# nrf54lm20a_enga_application register map
Vendor: Nordic Semiconductor; Series: nrf54l; File version: 1
CPU: CM33 r0p4, little endian, MPU, FPU, 3 interrupt priority bits, 270 interrupts, 4 SAU regions
Registers are 32-bit, read-write, reset 0x0 unless marked. A register's access mark holds for its fields unless they carry their own. Offsets are from the block's base; [hi:lo] are bit positions; lines under a group give offsets from that group; 'fields as' and 'values as' point back to an identical list.

## GLOBAL_PDM20_NS — Pulse Density Modulation (Digital Microphone) Interface 0
Base 0x400D0000
Same registers: GLOBAL_PDM21_NS 0x400D1000, GLOBAL_PDM20_S 0x500D0000, GLOBAL_PDM21_S 0x500D1000
0x00 TASKS_START wo — Starts continuous PDM transfer
  [0] TASKS_START
    1=Trigger task
0x04 TASKS_STOP wo — Stops PDM transfer
  [0] TASKS_STOP
    1=Trigger task
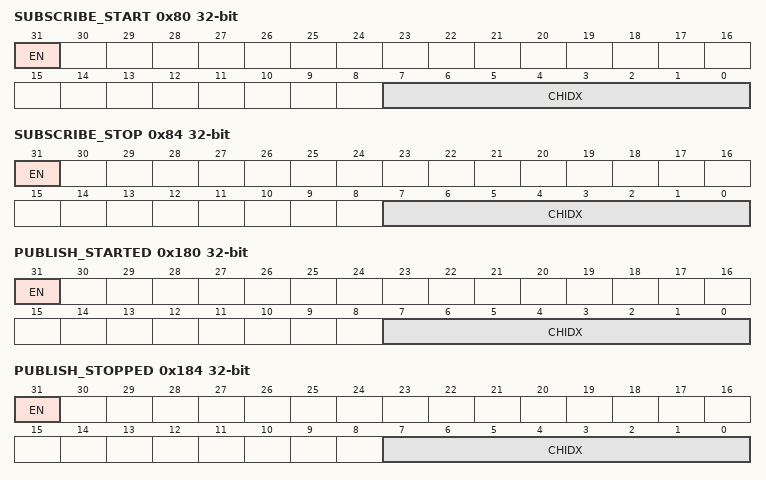
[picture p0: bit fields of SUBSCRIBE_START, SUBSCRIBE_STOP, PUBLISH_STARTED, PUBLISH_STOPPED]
0x80 SUBSCRIBE_START — Subscribe configuration for task START
  [31] EN
    0=Disabled (Disable subscription); 1=Enabled (Enable subscription)
  [7:0] CHIDX — DPPI channel that task START will subscribe to
0x84 SUBSCRIBE_STOP — Subscribe configuration for task STOP
  [31] EN
    values as SUBSCRIBE_START.EN
  [7:0] CHIDX — DPPI channel that task STOP will subscribe to
0x100 EVENTS_STARTED — PDM transfer has started
  [0] EVENTS_STARTED
    0=NotGenerated (Event not generated); 1=Generated (Event generated)
0x104 EVENTS_STOPPED — PDM transfer has finished
  [0] EVENTS_STOPPED
    values as EVENTS_STARTED.EVENTS_STARTED
0x108 EVENTS_END — The PDM has written the last sample specified by SAMPLE.MAXCNT (or the last sample after a STOP task has been received) to Data RAM
  [0] EVENTS_END
    values as EVENTS_STARTED.EVENTS_STARTED
0x10C EVENTS_OVERRUN — Samples lost due to DMA destination not available
  [0] EVENTS_OVERRUN
    values as EVENTS_STARTED.EVENTS_STARTED
0x110 EVENTS_DMA group — Peripheral events.
  0x00 BUSERROR — This event is generated if an error occurs during the bus transfer. This event is generated on an AHB / AXI error response.
    [0] BUSERROR
      values as EVENTS_STARTED.EVENTS_STARTED
0x180 PUBLISH_STARTED — Publish configuration for event STARTED
  [31] EN
    0=Disabled (Disable publishing); 1=Enabled (Enable publishing)
  [7:0] CHIDX — DPPI channel that event STARTED will publish to
0x184 PUBLISH_STOPPED — Publish configuration for event STOPPED
  [31] EN
    values as PUBLISH_STARTED.EN
  [7:0] CHIDX — DPPI channel that event STOPPED will publish to
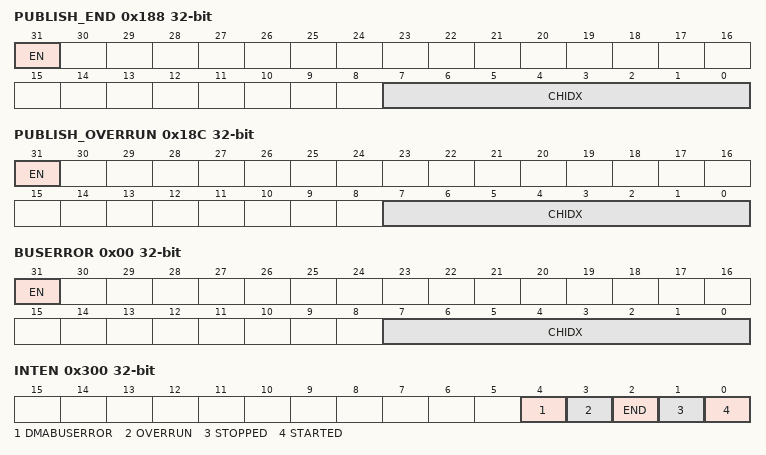
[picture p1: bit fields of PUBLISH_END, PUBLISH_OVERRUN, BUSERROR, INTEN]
0x188 PUBLISH_END — Publish configuration for event END
  [31] EN
    values as PUBLISH_STARTED.EN
  [7:0] CHIDX — DPPI channel that event END will publish to
0x18C PUBLISH_OVERRUN — Publish configuration for event OVERRUN
  [31] EN
    values as PUBLISH_STARTED.EN
  [7:0] CHIDX — DPPI channel that event OVERRUN will publish to
0x190 PUBLISH_DMA group — Publish configuration for events
  0x00 BUSERROR — Publish configuration for event DMA.BUSERROR
    [31] EN
      values as PUBLISH_STARTED.EN
    [7:0] CHIDX — DPPI channel that event DMA.BUSERROR will publish to
0x300 INTEN — Enable or disable interrupt
  [all] fields
    0=Disabled; 1=Enabled
  [4] DMABUSERROR — Enable or disable interrupt for event DMABUSERROR
  [3] OVERRUN — Enable or disable interrupt for event OVERRUN
  [2] END — Enable or disable interrupt for event END
  [1] STOPPED — Enable or disable interrupt for event STOPPED
  [0] STARTED — Enable or disable interrupt for event STARTED
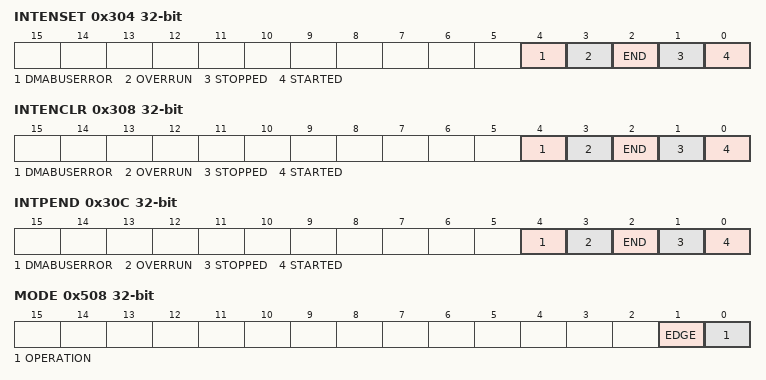
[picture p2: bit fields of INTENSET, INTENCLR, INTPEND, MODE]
0x304 INTENSET — Enable interrupt
  [all] fields
    on read: 0=Disabled (Read: Disabled); 1=Enabled (Read: Enabled) | on write: 1=Set (Enable)
  [4] DMABUSERROR — Write '1' to enable interrupt for event DMABUSERROR
  [3] OVERRUN — Write '1' to enable interrupt for event OVERRUN
  [2] END — Write '1' to enable interrupt for event END
  [1] STOPPED — Write '1' to enable interrupt for event STOPPED
  [0] STARTED — Write '1' to enable interrupt for event STARTED
0x308 INTENCLR — Disable interrupt
  [all] fields
    on read: 0=Disabled (Read: Disabled); 1=Enabled (Read: Enabled) | on write: 1=Clear (Disable)
  [4] DMABUSERROR — Write '1' to disable interrupt for event DMABUSERROR
  [3] OVERRUN — Write '1' to disable interrupt for event OVERRUN
  [2] END — Write '1' to disable interrupt for event END
  [1] STOPPED — Write '1' to disable interrupt for event STOPPED
  [0] STARTED — Write '1' to disable interrupt for event STARTED
0x30C INTPEND ro — Pending interrupts
  [all] fields
    on read: 0=NotPending (Read: Not pending); 1=Pending (Read: Pending)
  [4] DMABUSERROR — Read pending status of interrupt for event DMABUSERROR
  [3] OVERRUN — Read pending status of interrupt for event OVERRUN
  [2] END — Read pending status of interrupt for event END
  [1] STOPPED — Read pending status of interrupt for event STOPPED
  [0] STARTED — Read pending status of interrupt for event STARTED
0x500 ENABLE — PDM module enable register
  [0] ENABLE — Enable or disable PDM module
    0=Disabled; 1=Enabled
0x508 MODE — Defines the routing of the connected PDM microphone signals
  [1] EDGE — Defines on which PDM_CLK edge left (or mono) is sampled.
    0=LeftFalling (Left (or mono) is sampled on falling edge of PDM_CLK); 1=LeftRising (Left (or mono) is sampled on rising edge of PDM_CLK)
  [0] OPERATION — Mono or stereo operation Mono also disables the gated clock to the right filter bank
    0=Stereo (Sample and store one pair (left + right) of 16-bit samples per RAM word R=[31:16]; L=[15:0]); 1=Mono (Sample and store two successive left samples (16 bits each) per RAM word L1=[31:16]; L0=[15:0])
0x510 RXDLDATA ro — Left sample from filter output
  [15:0] RXDLDATA
0x514 RXDRDATA ro — Right sample from filter output
  [15:0] RXDRDATA
0x518 GAINL reset 0x28 — Left output gain adjustment
  [6:0] GAINL — Left output gain adjustment, in 0.5 dB steps, around the default module gain (see electrical parameters) 0x00 -20 dB gain adjust 0x01 -19.5 dB gain adjust (...) 0x27 -0.5 dB gain adjust 0x28 0 dB gain adjust 0x29 +0.5 dB gain adjust (...) 0x4F +19.5 dB gain adjust 0x50 +20 dB gain adjust
    0=MinGain (-20 dB gain adjustment (minimum)); 40=DefaultGain (0 dB gain adjustment); 80=MaxGain (+20 dB gain adjustment (maximum))
0x51C GAINR reset 0x28 — Right output gain adjustment
  [6:0] GAINR — Right output gain adjustment, in 0.5 dB steps, around the default module gain (see electrical parameters)
    values as GAINL.GAINL
0x520 RATIO reset 0x2 — Selects the decimation ratio between PDM_CLK and output sample rate. When RATIO is selected to be 'custom', the decimation rate should be set using the FILTER.CTRL field before setting the RATIO to 7 Change PRESCALER.DIVISOR accordingly.
  [2:0] RATIO — Selects the decimation ratio between PDM_CLK and output sample rate
    0=Ratio of 48; 1=Ratio of 50; 2=Ratio of 64; 3=Ratio of 80; 4=Ratio of 96; 5=Ratio of 150; 6=Ratio of 192; 7=Custom. The decimation rate can be changed using the FILTER.CTRL[31:25] bits
0x524 FILTER group — Unspecified
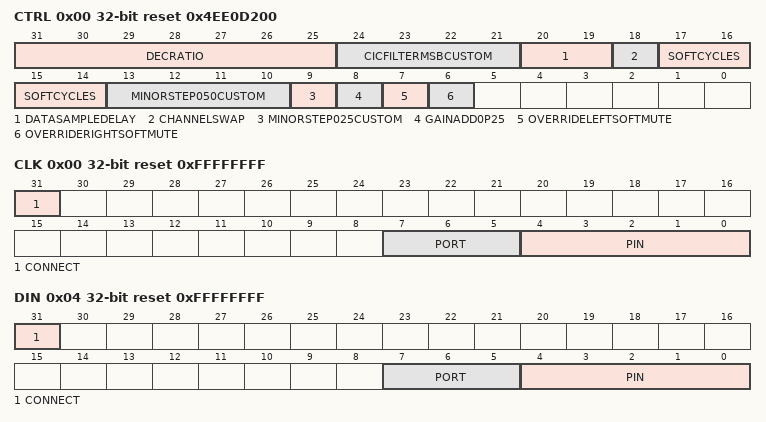
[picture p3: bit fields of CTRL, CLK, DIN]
  0x00 CTRL reset 0x4EE0D200 — Aditional PDM configurability
    [31:25] DECRATIO — Configures decimation ratio to any even number between 6 and 256
    [24:21] CICFILTERMSBCUSTOM — Defines MSB for CIC fliter when RATIO is set to 'custom'
      0=Range0 (OSR range low 4 OSR range high 32); 1=Range1 (OSR range low 34 OSR range high 36); 2=Range2 (OSR range low 38 OSR range high 42); 3=Range3 (OSR range low 44 OSR range high 48); 4=Range4 (OSR range low 50 OSR range high 54); 5=Range5 (OSR range low 56 OSR range high 64); 6=Range6 (OSR range low 66 OSR range high 72); 7=Range7 (OSR range low 74 OSR range high 84); 8=Range8 (OSR range low 86 OSR range high 96); 9=Range9 (OSR range low 98 OSR range high 110); 10=Range10 (OSR range low 112 OSR range high 128); 11=Range11 (OSR range low 130 OSR range high 146); 12=Range12 (OSR range low 148 OSR range high 168); 13=Range13 (OSR range low 170 OSR range high 194); 14=Range14 (OSR range low 196 OSR range high 222); 15=Range15 (OSR range low 224 OSR range high 256)
    [20:19] DATASAMPLEDELAY — Input data sampling point delay in PDM_CLK cycels
      0=NoDelay (No added delay); 1=DelayOnLeft (1 clock cycle delay on left channel); 2=DelayOnRight (1 clock cycle delay on right channel); 3=DelayOnBoth (1 clock cycle delay on both channels)
    [18] CHANNELSWAP — NOT USED
      0=NoSwap (Left to left, right to right); 1=Swapped connection
    [17:14] SOFTCYCLES — Custom number of cycles for soft gain/mute function 32*(Multiplication+1) steps
    [13:10] MINORSTEP050CUSTOM — Compensates Gain with +0.5dB steps
    [9] MINORSTEP025CUSTOM — Compensates Gain with +0.25dB
      0=Disable (Nothing added); 1=Enable (+0.25dB added)
    [8] GAINADD0P25 — Add +0.25dB to the gain stage
      0=Disable (Nothing added); 1=Enable (+0.25dB added)
    [7] OVERRIDELEFTSOFTMUTE — Override soft mute enable for left channel
      0=Disable (No action); 1=Enable (override and disable soft mute)
    [6] OVERRIDERIGHTSOFTMUTE — Override soft mute enable for right channel
      values as OVERRIDELEFTSOFTMUTE
  0x04 HPPOLE reset 0x5 — Settings for the high-pass filter
    [3:0] HPPOLE — Settings for the high-pass filter -3dB gain pole, assuming filter source clock of 16KHz
      15=p0p16 (0.16 Hz); 14=p0p32 (0.32 Hz); 13=p0p64 (0.64 Hz); 12=p1p25 (1.25 Hz); 11=p2p5 (2.5 Hz); 10=p5 (5 Hz); 9=p10 (10 Hz); 8=p20 (20 Hz); 7=p40 (40 Hz); 6=p79 (79 Hz); 5=p157 (157 Hz); 4=p310 (310 Hz); 3=p603 (603 Hz); 2=p1152 (1152 Hz); 1=p2110 (2110 Hz)
  0x08 HPDISABLE reset 0x1 — High pass filter disable
    [0] DISABLE
      0=Enable (High pass filter enabled); 1=Disable (High pass filter disabled)
  0x0C SOFTMUTE — Soft mute function
    [0] ENABLE
      0=Disabled (Disable soft mute function); 1=Enabled (Enable soft mute function)
  0x10 SOFTCYCLES reset 0x2 — Soft mute settings
    [2:0] DISABLE — Soft mute settings: amount of cycles for transition
      0=s2 (2 filter source clock cycles); 1=s8 (8 filter source clock cycles); 2=s32 (32 filter source clock cycles); 3=s64 (64 filter source clock cycles); 4=s128 (128 filter source clock cycles); 5=s256 (256 filter source clock cycles); 6=s512 (512 filter source clock cycles); 7=custom (The number of cycles can be set using FILTER.CTRL[17:14] bits)
  0x14 SAMPLEDELAY — Input Data Sampling with Number of ckFilterL (double frequency of PDM_CLK) Clock Cycle Delay. Optionally,input sample point can be delayed independently on left and right channels using FILTER:CTRL[20:19] bits
    [0] DELAY — Input Data Sampling with Number of ckFilterL (double frequency of PDM_CLK) Clock Cycle Delay
      0=no_delay; 1=1 cycle
0x540 PSEL group — Unspecified
  0x00 CLK reset 0xFFFFFFFF — Pin number configuration for PDM CLK signal
    [31] CONNECT — Connection
      1=Disconnected; 0=Connected
    [7:5] PORT — Port number
    [4:0] PIN — Pin number
  0x04 DIN reset 0xFFFFFFFF — Pin number configuration for PDM DIN signal
    fields as PSEL.CLK
0x54C CLKSELECT — Master clock generator configuration
  [0] SRC — Master clock source selection
    0=PCLK32M (32 MHz peripheral clock); 1=ACLK (24 MHz peripheral clock)
0x560 SAMPLE group — Unspecified
  0x00 PTR — RAM address pointer to write samples to with EasyDMA
    [31:0] SAMPLEPTR — Address to write PCM samples to over DMA
  0x04 MAXCNT — Number of bytes to allocate memory for in EasyDMA mode
    [14:0] BUFFSIZE — Length of DMA RAM allocation in number of bytes
  0x08 AMOUNT ro — Number of bytes transferred in the last transaction, updated after the END event.
    [14:0] AMOUNT — Number of bytes transferred in the last transaction. In case of NACK error, includes the NACK'ed byte
0x580 PRESCALER reset 0x4 — The prescaler is used to set the PDM frequency
  [7:0] DIVISOR — Core clock to PDM divisor
0x700 DMA group — Unspecified
  0x00 TERMINATEONBUSERROR — Terminate the transaction if a BUSERROR event is detected.
    [0] ENABLE
      0=Disabled; 1=Enabled
  0x04 BUSERRORADDRESS ro — Address of transaction that generated the last BUSERROR event.
    [31:0] ADDRESS
